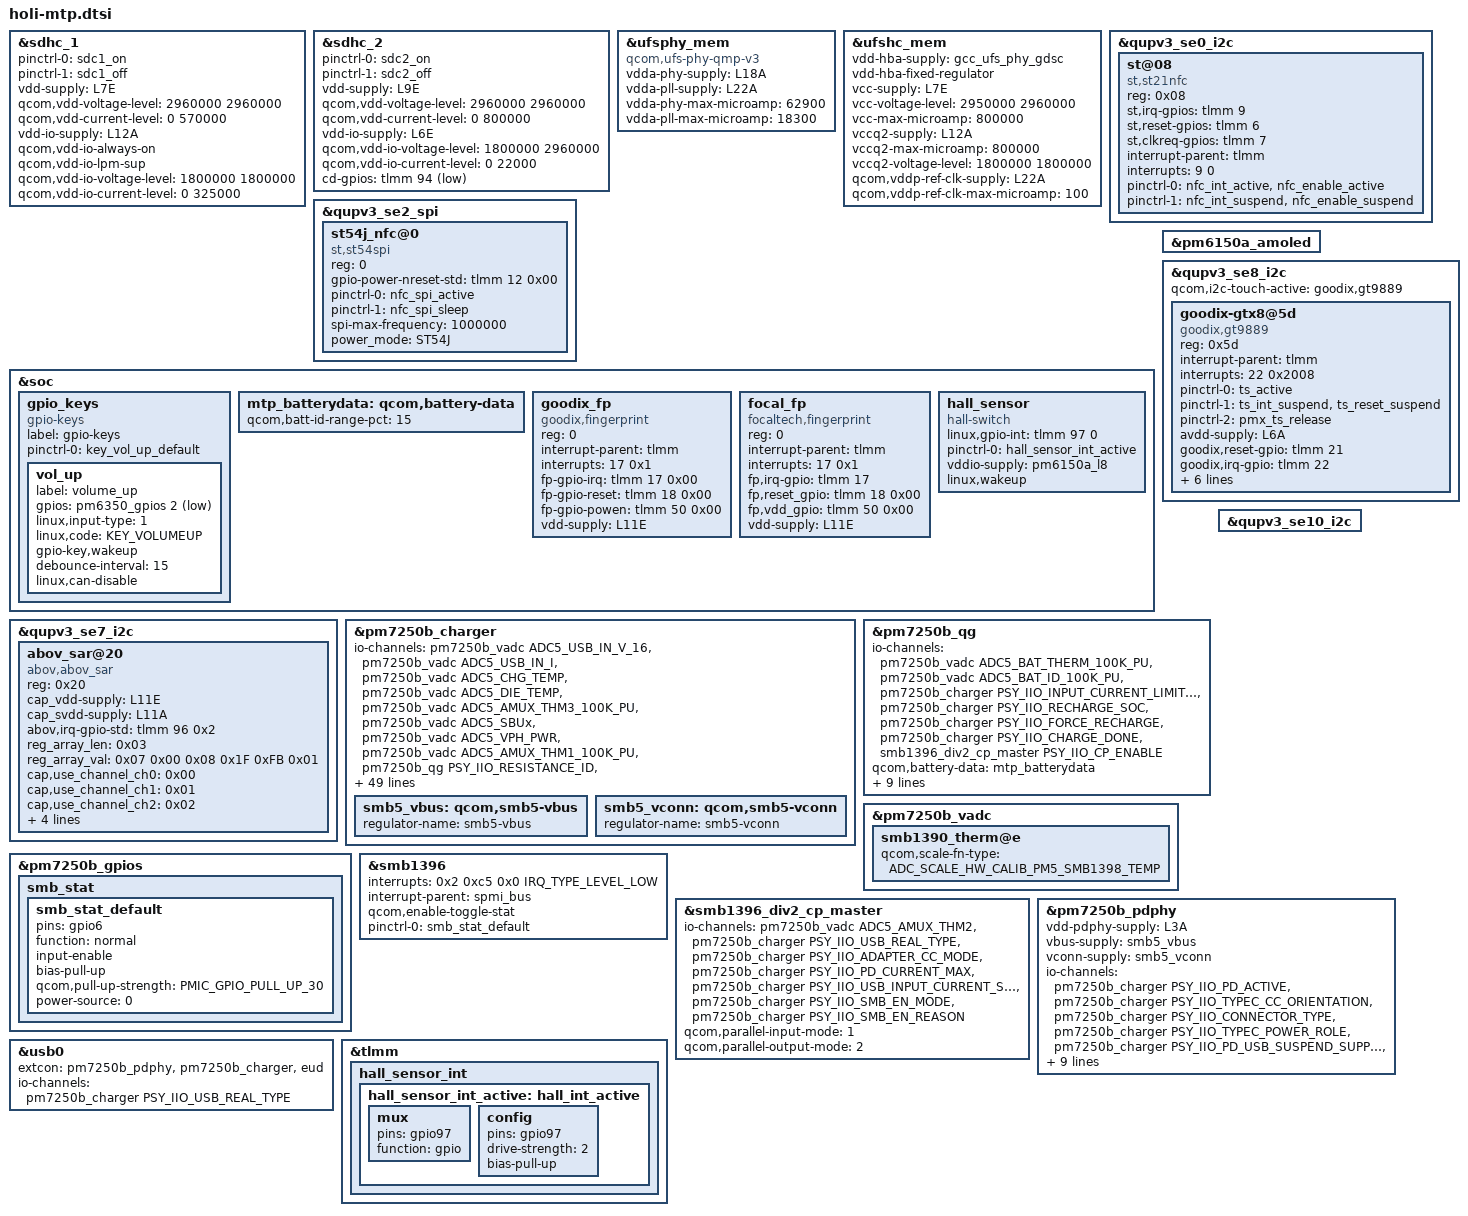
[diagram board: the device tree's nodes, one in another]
#include "holi-audio-overlay.dtsi"
#include <dt-bindings/gpio/gpio.h>
#include <dt-bindings/input/linux-event-codes.h>
#include "holi-pmic-overlay.dtsi"
#include "display/holi-sde-display-mtp.dtsi"
#include "holi-thermal-overlay.dtsi"
#include <dt-bindings/iio/qti_power_supply_iio.h>

#include "camera/holi-camera-sensor-mtp.dtsi"

&sdhc_1 {
	status = "ok";

	pinctrl-names = "default", "sleep";
	pinctrl-0 = <&sdc1_on>;
	pinctrl-1 = <&sdc1_off>;

	vdd-supply = <&L7E>;
	qcom,vdd-voltage-level = <2960000 2960000>;
	qcom,vdd-current-level = <0 570000>;

	vdd-io-supply = <&L12A>;
	qcom,vdd-io-always-on;
	qcom,vdd-io-lpm-sup;
	qcom,vdd-io-voltage-level = <1800000 1800000>;
	qcom,vdd-io-current-level = <0 325000>;
};

&sdhc_2 {
	status = "ok";

	pinctrl-names = "default", "sleep";
	pinctrl-0 = <&sdc2_on>;
	pinctrl-1 = <&sdc2_off>;

	vdd-supply = <&L9E>;
	qcom,vdd-voltage-level = <2960000 2960000>;
	qcom,vdd-current-level = <0 800000>;

	vdd-io-supply = <&L6E>;
	qcom,vdd-io-voltage-level = <1800000 2960000>;
	qcom,vdd-io-current-level = <0 22000>;

	cd-gpios = <&tlmm 94 GPIO_ACTIVE_LOW>;
};

&ufsphy_mem {
		compatible = "qcom,ufs-phy-qmp-v3";

		vdda-phy-supply = <&L18A>;
		vdda-pll-supply = <&L22A>;
		vdda-phy-max-microamp = <62900>;
		vdda-pll-max-microamp = <18300>;

		status = "ok";
};

&ufshc_mem {
		vdd-hba-supply = <&gcc_ufs_phy_gdsc>;
		vdd-hba-fixed-regulator;

		vcc-supply = <&L7E>;
		vcc-voltage-level = <2950000 2960000>;
		vcc-max-microamp = <800000>;

		vccq2-supply = <&L12A>;
		vccq2-max-microamp = <800000>;
		vccq2-voltage-level = <1800000 1800000>;

		qcom,vddp-ref-clk-supply = <&L22A>;
		qcom,vddp-ref-clk-max-microamp = <100>;

		status = "ok";
};

//lianghai.shi ST54J NFC modify start
&qupv3_se0_i2c {
	status = "ok";
	#address-cells = <1>;
	#size-cells = <0>;
	st@08 {
		compatible = "st,st21nfc";
		reg = <0x08>;
		st,irq-gpios = <&tlmm 9 0x00>;
		st,reset-gpios = <&tlmm 6 0x00>;
		st,clkreq-gpios = <&tlmm 7 0x00>;
		interrupt-parent = <&tlmm>;
		interrupts = <9 0>;
		interrupt-names = "nfc_irq";
		pinctrl-names = "nfc_active", "nfc_suspend";
		pinctrl-0 = <&nfc_int_active &nfc_enable_active>;
		pinctrl-1 = <&nfc_int_suspend &nfc_enable_suspend>;
	};
};

&qupv3_se2_spi {
	status = "ok";
	st54j_nfc@0 {
		compatible = "st,st54spi";
		reg = <0>;
		gpio-power-nreset-std = <&tlmm 12 0x00>;
		pinctrl-names = "nfc_spi_active", "nfc_spi_sleep";
		pinctrl-0 = <&nfc_spi_active>;
		pinctrl-1 = <&nfc_spi_sleep>;
		spi-max-frequency = <1000000>;
		power_mode = "ST54J";
	};
};
//lianghai.shi ST54J NFC modify end

&soc {
	gpio_keys {
		compatible = "gpio-keys";
		label = "gpio-keys";

		pinctrl-names = "default";
		pinctrl-0 = <&key_vol_up_default>;

		vol_up {
			label = "volume_up";
			gpios = <&pm6350_gpios 2 GPIO_ACTIVE_LOW>;
			linux,input-type = <1>;
			linux,code = <KEY_VOLUMEUP>;
			gpio-key,wakeup;
			debounce-interval = <15>;
			linux,can-disable;
		};
	};

	mtp_batterydata: qcom,battery-data {
		qcom,batt-id-range-pct = <15>;
		#include "qg-batterydata-2750mah-p710-wk.dtsi"
		#include "qg-batterydata-2750mah-p710-byd.dtsi"
	};

	//{ Modify by Richard for fp
	goodix_fp {
		compatible = "goodix,fingerprint";
		reg = <0>;
		interrupt-parent = <&tlmm>;
		interrupts = <17 0x1>;
		fp-gpio-irq = <&tlmm 17 0x00>;
		fp-gpio-reset = <&tlmm 18 0x00>;
		fp-gpio-powen = <&tlmm 50 0x00>;
		vdd-supply = <&L11E>;
		status = "ok";
	};

	focal_fp {
		compatible = "focaltech,fingerprint";
		reg = <0>;
		interrupt-parent = <&tlmm>;
		interrupts = <17 0x1>;
		fp,irq-gpio = <&tlmm 17 0x00>;
		fp,reset_gpio = <&tlmm 18 0x00>;
		fp,vdd_gpio = <&tlmm 50 0x00>;
		vdd-supply = <&L11E>;
		status = "ok";
	};
	//}
};

&pm6150a_amoled {
	status = "ok";
};

//{ Richard add for sar sensor
&qupv3_se7_i2c {
	status = "ok";
	abov_sar@20 {
		status = "ok";
		compatible = "abov,abov_sar";
		reg = <0x20>;
		cap_vdd-supply = <&L11E>;
		cap_svdd-supply = <&L11A>;
		//abov,irq-gpio = <96>;
		abov,irq-gpio-std = <&tlmm 96 0x2>;
		//pinctrl-names = "abov_int_default";
		//pinctrl-0 = <&abov_sar_gpio_pins>;
		reg_array_len = <0x03>;
		reg_array_val = <0x07 0x00 0x08 0x1F 0xFB 0x01>;
		cap,use_channel_ch0 = <0x00>;
		cap,use_channel_ch1 = <0x01>;
		cap,use_channel_ch2 = <0x02>;
		ch0_name = "grip_sensor_bottom";
		ch1_name = "grip_sensor_topleft";
		ch2_name = "grip_sensor_topright";
		cap,firmware_name="AbovCapSense";
	};
};
//}

&qupv3_se8_i2c {
	status = "okay";
/*feiyu.zhu for p780 TP bring up start*/
	/*
	qcom,i2c-touch-active="synaptics,tcm-i2c";

	synaptics_tcm@20 {
		compatible = "synaptics,tcm-i2c";
		reg = <0x20>;
		interrupt-parent = <&tlmm>;
		interrupts = <22 0x2008>;
		pinctrl-names = "pmx_ts_active","pmx_ts_suspend",
					"pmx_ts_release";
		pinctrl-0 = <&ts_active>;
		pinctrl-1 = <&ts_int_suspend &ts_reset_suspend>;
		pinctrl-2 = <&pmx_ts_release>;
		vdd-supply = <&L11A>;
		avdd-supply = <&L6A>;
		synaptics,pwr-reg-name = "avdd";
		synaptics,bus-reg-name = "vdd";
		synaptics,irq-gpio = <&tlmm 22 0x2008>;
		synaptics,irq-on-state = <0>;
		synaptics,reset-gpio = <&tlmm 21 0x00>;
		synaptics,reset-on-state = <0>;
		synaptics,reset-active-ms = <20>;
		synaptics,reset-delay-ms = <200>;
		synaptics,power-delay-ms = <200>;
		synaptics,ubl-i2c-addr = <0x20>;
		synaptics,extend_report;
		synaptics,firmware-name = "synaptics_firmware.img";

		panel = <&dsi_rm69299_amoled_p780_cmd>;
	};
	*/
	qcom,i2c-touch-active="goodix,gt9889";

	goodix-gtx8@5d {
		compatible = "goodix,gt9889";
		reg = <0x5d>;
		interrupt-parent = <&tlmm>;
		interrupts = <22 0x2008>;
		pinctrl-names = "pmx_ts_active","pmx_ts_suspend",
			"pmx_ts_release";
		pinctrl-0 = <&ts_active>;
		pinctrl-1 = <&ts_int_suspend &ts_reset_suspend>;
		pinctrl-2 = <&pmx_ts_release>;
		avdd-supply = <&L6A>;
		goodix,reset-gpio = <&tlmm 21 0x00>;
		goodix,irq-gpio = <&tlmm 22 0x2008>;
		goodix,irq-flags = <2>; /* 1:trigger rising, 2:trigger falling;*/
		goodix,panel-max-x = <720>;
		goodix,panel-max-y = <1520>;
		goodix,panel-max-w = <255>;
		goodix,avdd-name = "avdd";
		//goodix,x2x;
		//goodix,y2y;
		
		panel = <&dsi_rm69299_amoled_p780_cmd>;
	};
/*feiyu.zhu for p780 TP bring up end*/
};

&pm7250b_charger {
	status = "ok";
	#io-channel-cells = <1>;
	io-channels = <&pm7250b_vadc ADC5_USB_IN_V_16>,
		      <&pm7250b_vadc ADC5_USB_IN_I>,
		      <&pm7250b_vadc ADC5_CHG_TEMP>,
		      <&pm7250b_vadc ADC5_DIE_TEMP>,
		      <&pm7250b_vadc ADC5_AMUX_THM3_100K_PU>,
		      <&pm7250b_vadc ADC5_SBUx>,
		      <&pm7250b_vadc ADC5_VPH_PWR>,
		      <&pm7250b_vadc ADC5_AMUX_THM1_100K_PU>,
		      <&pm7250b_qg PSY_IIO_RESISTANCE_ID>,
		      <&pm7250b_qg PSY_IIO_VOLTAGE_NOW>,
		      <&pm7250b_qg PSY_IIO_TEMP>,
		      <&pm7250b_qg PSY_IIO_CAPACITY>,
		      <&pm7250b_qg PSY_IIO_VOLTAGE_OCV>,
		      <&pm7250b_qg PSY_IIO_VOLTAGE_AVG>,
		      <&pm7250b_qg PSY_IIO_DEBUG_BATTERY>,
		      <&pm7250b_qg PSY_IIO_REAL_CAPACITY>,
		      <&pm7250b_qg PSY_IIO_CC_SOC>,
		      <&pm7250b_qg PSY_IIO_CURRENT_NOW>,
		      <&pm7250b_qg PSY_IIO_VOLTAGE_MAX>,
		      <&pm7250b_qg PSY_IIO_CHARGE_FULL>,
		      <&pm7250b_qg PSY_IIO_CHARGE_COUNTER>,
		      <&pm7250b_qg PSY_IIO_CYCLE_COUNT>,
		      <&pm7250b_qg PSY_IIO_CHARGE_FULL_DESIGN>,
		      <&pm7250b_qg PSY_IIO_TIME_TO_FULL_NOW>,
		      <&smb1396_div2_cp_master PSY_IIO_PARALLEL_MODE>,
		      <&smb1396_div2_cp_master PSY_IIO_PARALLEL_OUTPUT_MODE>,
		      <&smb1396_div2_cp_master PSY_IIO_MIN_ICL>,
		      <&smb1396_div2_cp_master PSY_IIO_CP_SWITCHER_EN>,
		      <&smb1396_div2_cp_master PSY_IIO_CP_ENABLE>,
		      <&smb1396_div2_cp_master PSY_IIO_CP_ILIM>,
		      <&smb1396_div2_cp_master PSY_IIO_CP_DIE_TEMP>;
	io-channel-names = "usb_in_voltage",
			   "usb_in_current",
			   "chg_temp",
			   "die_temp",
			   "conn_temp",
			   "sbux_res",
			   "vph_voltage",
			   "skin_temp",
			   "resistance_id",
			   "voltage_now",
			   "temp",
			   "capacity",
			   "voltage_ocv",
			   "voltage_avg",
			   "debug_battery",
			   "real_capacity",
			   "cc_soc",
			   "current_now",
			   "voltage_max",
			   "charge_full",
			   "charge_counter",
			   "cycle_count",
			   "charge_full_design",
			   "time_to_full_now",
			   "cp_parallel_mode",
			   "cp_parallel_output_mode",
			   "cp_min_icl",
			   "cp_switcher_en",
			   "cp_enable",
			   "cp_ilim",
			   "cp_die_temp";
	qcom,battery-data = <&mtp_batterydata>;
	qcom,sec-charger-config = <0>;		       // pony.ma, 0:No secondary charger,1:SMB1390,2:SMB1355, DATE20210414
	qcom,auto-recharge-soc = <95>;
	qcom,step-charging-enable;
	qcom,sw-jeita-enable;
	qcom,charger-temp-max = <800>;
	qcom,smb-temp-max = <800>;
	qcom,suspend-input-on-debug-batt;
	qcom,fcc-stepping-enable;
	qcom,fcc-step-delay-ms = <100>;
	qcom,fcc-step-size-ua = <100000>;
	qcom,smb-internal-pull-kohm = <0>;
	qcom,en-skin-therm-mitigation;
	qcom,hvdcp3-standalone-config;

	// pony.ma, charge config, DATE20210414-01 START
//	qcom,hvdcp-disable;
	qcom,fcc-max-ua = <2700000>;	   	//fast current charge in battery profile config
	qcom,usb-icl-ua = <2000000>;		//usb input limit
	qcom,fv-max-uv = <4400000>;		//float voltage in battery profile config
	qcom,otg-cl-ua = <500000>;		//otg limit current
	qcom,float-option = <1>;			//1,DCP;2,SDP;3,disable charging;4,suspend usb input
	qcom,dcp-icl-en = <1>;
	qcom,dcp-icl-ua-1 = <2000000>;
	qcom,float-icl-ua = <1000000>;
	qcom,chg-term-src = <1>;		//tcc config
	qcom,chg-term-current-ma = <(-100)>;	//tcc is 100mA
	qcom,speed-current = <2700000 1800000
				1600000 1400000
				1200000 1000000
				700000  500000
				400000  0>;			//for scc by pony DATE20210414
	// pony.ma, DATE20210414-01 END
};

&pm7250b_qg {
	status = "ok";
	#io-channel-cells = <1>;
	io-channels = <&pm7250b_vadc ADC5_BAT_THERM_100K_PU>,
		      <&pm7250b_vadc ADC5_BAT_ID_100K_PU>,
		      <&pm7250b_charger PSY_IIO_INPUT_CURRENT_LIMITED>,
		      <&pm7250b_charger PSY_IIO_RECHARGE_SOC>,
		      <&pm7250b_charger PSY_IIO_FORCE_RECHARGE>,
		      <&pm7250b_charger PSY_IIO_CHARGE_DONE>,
		      <&smb1396_div2_cp_master PSY_IIO_CP_ENABLE>;
	io-channel-names = "batt-therm",
			   "batt-id",
			   "input_current_limited",
			   "recharge_soc",
			   "force_recharge",
			   "charge_done",
			   "cp_charging_enabled";
	qcom,battery-data = <&mtp_batterydata>;
	qcom,qg-iterm-ma = <350>;
	qcom,hold-soc-while-full;
	qcom,linearize-soc;
	qcom,cl-feedback-on;
	qcom,tcss-enable;
	qcom,fvss-enable;
	qcom,fvss-vbatt-mv = <3300>;
	qcom,bass-enable;
	qcom,use-cp-iin-sns;
};

&pm7250b_vadc {
	smb1390_therm@e {
		qcom,scale-fn-type = <ADC_SCALE_HW_CALIB_PM5_SMB1398_TEMP>;
	};
};

&pm7250b_gpios {
	smb_stat {
		smb_stat_default: smb_stat_default {
			pins = "gpio6";
			function = "normal";
			input-enable;
			bias-pull-up;
			qcom,pull-up-strength = <PMIC_GPIO_PULL_UP_30>;
			power-source = <0>;
		};
	};
};

&qupv3_se10_i2c {
	status = "ok";
	#include "smb1398.dtsi"
};

&smb1396 {
	interrupts = <0x2 0xc5 0x0 IRQ_TYPE_LEVEL_LOW>;
	interrupt-parent = <&spmi_bus>;
	interrupt-names = "smb1396";
	pinctrl-names = "default";
	qcom,enable-toggle-stat;
	pinctrl-0 = <&smb_stat_default>;
	status = "ok";
};

&smb1396_div2_cp_master {
	io-channels = <&pm7250b_vadc ADC5_AMUX_THM2>,
		      <&pm7250b_charger PSY_IIO_USB_REAL_TYPE>,
		      <&pm7250b_charger PSY_IIO_ADAPTER_CC_MODE>,
		      <&pm7250b_charger PSY_IIO_PD_CURRENT_MAX>,
		      <&pm7250b_charger PSY_IIO_USB_INPUT_CURRENT_SETTLED>,
		      <&pm7250b_charger PSY_IIO_SMB_EN_MODE>,
		      <&pm7250b_charger PSY_IIO_SMB_EN_REASON>;
	io-channel-names = "die_temp",
			   "real_type",
			   "adapter_cc_mode",
			   "pd_current_max",
			   "input_current_settled",
			   "smb_en_mode",
			   "smb_en_reason";
	qcom,parallel-input-mode = <1>; /* USBIN */
	qcom,parallel-output-mode = <2>; /* VBAT */
	status = "ok";
};


&pm7250b_charger {
	dpdm-supply = <&qusb_phy0>;

	smb5_vbus: qcom,smb5-vbus {
		regulator-name = "smb5-vbus";
	};

	smb5_vconn: qcom,smb5-vconn {
		regulator-name = "smb5-vconn";
	};
};

&pm7250b_pdphy {
	vdd-pdphy-supply = <&L3A>;
	vbus-supply = <&smb5_vbus>;
	vconn-supply = <&smb5_vconn>;

	#io-channel-cells = <1>;
	io-channels = <&pm7250b_charger PSY_IIO_PD_ACTIVE>,
		      <&pm7250b_charger PSY_IIO_TYPEC_CC_ORIENTATION>,
		      <&pm7250b_charger PSY_IIO_CONNECTOR_TYPE>,
		      <&pm7250b_charger PSY_IIO_TYPEC_POWER_ROLE>,
		      <&pm7250b_charger PSY_IIO_PD_USB_SUSPEND_SUPPORTED>,
		      <&pm7250b_charger PSY_IIO_TYPEC_SRC_RP>,
		      <&pm7250b_charger PSY_IIO_PD_IN_HARD_RESET>,
		      <&pm7250b_charger PSY_IIO_PD_CURRENT_MAX>,
		      <&pm7250b_charger PSY_IIO_PR_SWAP>,
		      <&pm7250b_charger PSY_IIO_PD_VOLTAGE_MIN>,
		      <&pm7250b_charger PSY_IIO_PD_VOLTAGE_MAX>,
		      <&pm7250b_charger PSY_IIO_USB_REAL_TYPE>,
		      <&pm7250b_charger PSY_IIO_TYPEC_MODE>,
		      <&pm7250b_charger PSY_IIO_PE_START>;
	io-channel-names = "pd_active",
			   "typec_cc_orientation",
			   "connector_type",
			   "typec_power_role",
			   "pd_usb_suspend_supported",
			   "typec_src_rp",
			   "pd_in_hard_reset",
			   "pr_current_max",
			   "pr_swap",
			   "pd_voltage_min",
			   "pd_voltage_max",
			   "real_type",
			   "typec_mode",
			   "pe_start";
};

&usb0 {
	extcon = <&pm7250b_pdphy>, <&pm7250b_charger>, <&eud>;

	#io-channel-cells = <1>;
	io-channels= <&pm7250b_charger PSY_IIO_USB_REAL_TYPE>;
	io-channel-names = "chg_type";
};

&tlmm {
	hall_sensor_int {
		hall_sensor_int_active: hall_int_active {
			mux {
				pins = "gpio97";
				function = "gpio";
			};

			config {
				pins = "gpio97";
				drive-strength = <2>;
				bias-pull-up;
			};
		};
	};
};

&soc {
	hall_sensor {
		compatible = "hall-switch";
		linux,gpio-int = <&tlmm 97 0>;
		pinctrl-names = "default";
		pinctrl-0 = <&hall_sensor_int_active>;
		vddio-supply = <&pm6150a_l8>;
		linux,wakeup;

		status = "okay";
	};
};
